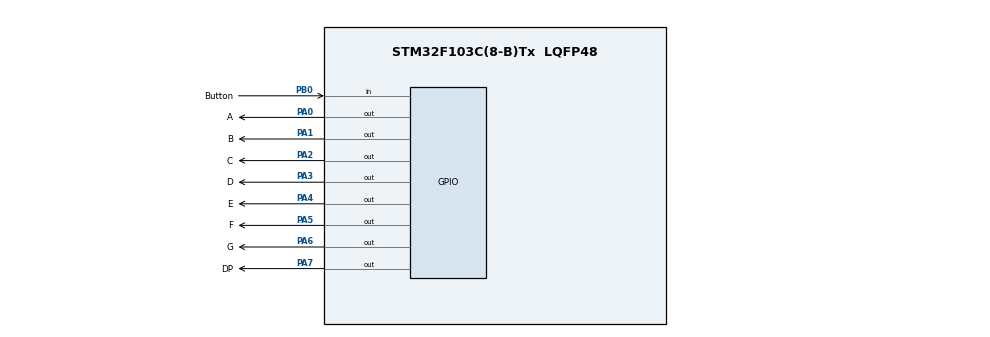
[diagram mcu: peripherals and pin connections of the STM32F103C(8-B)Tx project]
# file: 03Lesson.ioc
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Mcu.Family=STM32F1
Mcu.Name=STM32F103C(8-B)Tx
Mcu.Package=LQFP48
NVIC.PriorityGroup=NVIC_PRIORITYGROUP_4
PA0-WKUP.GPIO_Label=A
PA0-WKUP.Signal=GPIO_Output
PA1.GPIO_Label=B
PA1.Signal=GPIO_Output
PA13.Mode=Serial_Wire
PA13.Signal=SYS_JTMS-SWDIO
PA14.Mode=Serial_Wire
PA14.Signal=SYS_JTCK-SWCLK
PA2.GPIO_Label=C
PA2.Signal=GPIO_Output
PA3.GPIO_Label=D
PA3.Signal=GPIO_Output
PA4.GPIO_Label=E
PA4.Signal=GPIO_Output
PA5.GPIO_Label=F
PA5.Signal=GPIO_Output
PA6.GPIO_Label=G
PA6.Signal=GPIO_Output
PA7.GPIO_Label=DP
PA7.Signal=GPIO_Output
PB0.GPIO_Label=Button
PB0.Signal=GPIO_Input
ProjectManager.HeapSize=0x200
ProjectManager.StackSize=0x400
ProjectManager.TargetToolchain=Other Toolchains (GPDSC)
RCC.APB1Freq_Value=8000000
RCC.APB2Freq_Value=8000000
board=custom

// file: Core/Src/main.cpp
/* USER CODE BEGIN Header */
/**
  ******************************************************************************
  * @file           : main.c
  * @brief          : Main program body
  ******************************************************************************
  * @attention
  *
  * <h2><center>&copy; Copyright (c) 2020 STMicroelectronics.
  * All rights reserved.</center></h2>
  *
  * This software component is licensed by ST under BSD 3-Clause license,
  * the "License"; You may not use this file except in compliance with the
  * License. You may obtain a copy of the License at:
  *                        opensource.org/licenses/BSD-3-Clause
  *
  ******************************************************************************
  */
/* USER CODE END Header */
#include "main.h"

/* USER CODE BEGIN Includes */
#include "DigitLed.h"
/* USER CODE END Includes */

void SystemClock_Config(void);
static void MX_GPIO_Init(void);

int main(void)
{

  /* MCU Configuration--------------------------------------------------------*/

  /* Reset of all peripherals, Initializes the Flash interface and the Systick. */
  HAL_Init();

  /* Configure the system clock */
  SystemClock_Config();

  /* Initialize all configured peripherals */
  MX_GPIO_Init();
  /* USER CODE BEGIN 2 */
	DigitLed Display(A_GPIO_Port, A_Pin, B_GPIO_Port, B_Pin, C_GPIO_Port, C_Pin, D_GPIO_Port, D_Pin, E_GPIO_Port, E_Pin, F_GPIO_Port, F_Pin, G_GPIO_Port, G_Pin, DP_GPIO_Port, DP_Pin);
  /* USER CODE END 2 */

  /* Infinite loop */
  /* USER CODE BEGIN WHILE */
  while (1)
  {
	  for (uint8_t i = 0; i < 10; i++)
	  {
		  Display.print(i);
		  HAL_Delay(1000);
	  }

    /* USER CODE END WHILE */

  }
}

void SystemClock_Config(void)
{
  RCC_OscInitTypeDef RCC_OscInitStruct = {0};
  RCC_ClkInitTypeDef RCC_ClkInitStruct = {0};

  /** Initializes the RCC Oscillators according to the specified parameters
  * in the RCC_OscInitTypeDef structure.
  */
  RCC_OscInitStruct.OscillatorType = RCC_OSCILLATORTYPE_HSI;
  RCC_OscInitStruct.HSIState = RCC_HSI_ON;
  RCC_OscInitStruct.HSICalibrationValue = RCC_HSICALIBRATION_DEFAULT;
  RCC_OscInitStruct.PLL.PLLState = RCC_PLL_NONE;
  if (HAL_RCC_OscConfig(&RCC_OscInitStruct) != HAL_OK)
  {
    Error_Handler();
  }
  /** Initializes the CPU, AHB and APB buses clocks
  */
  RCC_ClkInitStruct.ClockType = RCC_CLOCKTYPE_HCLK|RCC_CLOCKTYPE_SYSCLK
                              |RCC_CLOCKTYPE_PCLK1|RCC_CLOCKTYPE_PCLK2;
  RCC_ClkInitStruct.SYSCLKSource = RCC_SYSCLKSOURCE_HSI;
  RCC_ClkInitStruct.AHBCLKDivider = RCC_SYSCLK_DIV1;
  RCC_ClkInitStruct.APB1CLKDivider = RCC_HCLK_DIV1;
  RCC_ClkInitStruct.APB2CLKDivider = RCC_HCLK_DIV1;

  if (HAL_RCC_ClockConfig(&RCC_ClkInitStruct, FLASH_LATENCY_0) != HAL_OK)
  {
    Error_Handler();
  }
}

static void MX_GPIO_Init(void)
{
  GPIO_InitTypeDef GPIO_InitStruct = {0};

  /* GPIO Ports Clock Enable */
  __HAL_RCC_GPIOA_CLK_ENABLE();
  __HAL_RCC_GPIOB_CLK_ENABLE();

  /*Configure GPIO pin Output Level */
  HAL_GPIO_WritePin(GPIOA, A_Pin|B_Pin|C_Pin|D_Pin
                          |E_Pin|F_Pin|G_Pin|DP_Pin, GPIO_PIN_RESET);

  /*Configure GPIO pins : A_Pin B_Pin C_Pin D_Pin
                           E_Pin F_Pin G_Pin DP_Pin */
  GPIO_InitStruct.Pin = A_Pin|B_Pin|C_Pin|D_Pin
                          |E_Pin|F_Pin|G_Pin|DP_Pin;
  GPIO_InitStruct.Mode = GPIO_MODE_OUTPUT_PP;
  GPIO_InitStruct.Pull = GPIO_NOPULL;
  GPIO_InitStruct.Speed = GPIO_SPEED_FREQ_LOW;
  HAL_GPIO_Init(GPIOA, &GPIO_InitStruct);

  /*Configure GPIO pin : Button_Pin */
  GPIO_InitStruct.Pin = Button_Pin;
  GPIO_InitStruct.Mode = GPIO_MODE_INPUT;
  GPIO_InitStruct.Pull = GPIO_NOPULL;
  HAL_GPIO_Init(Button_GPIO_Port, &GPIO_InitStruct);

}

void Error_Handler(void)
{
}

/************************ (C) COPYRIGHT STMicroelectronics *****END OF FILE****/
